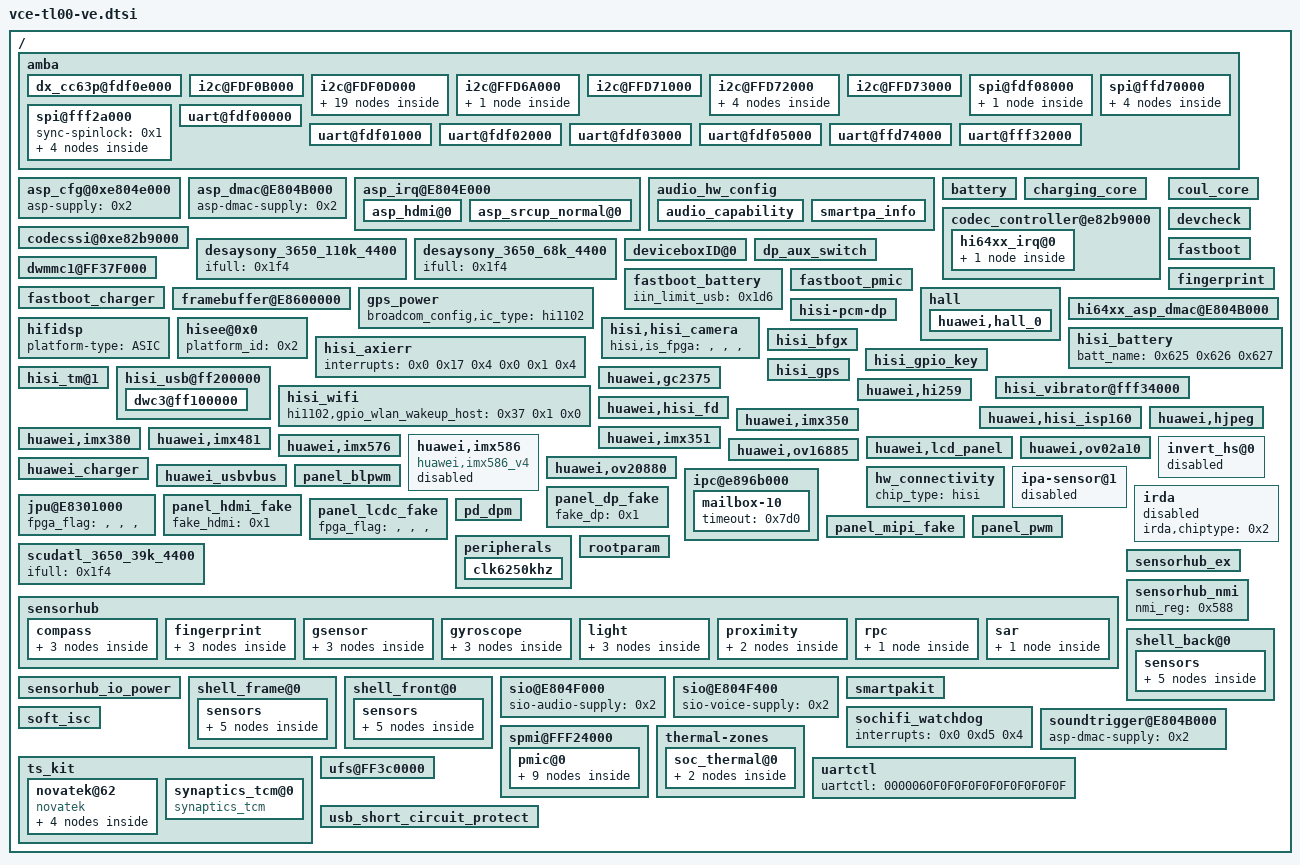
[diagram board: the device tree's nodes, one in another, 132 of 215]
// SPDX-License-Identifier: GPL-2.0
// Editable settings imported from vce-tl00-ve.dtbo.
/ {
	__symbols__ {
		ldo22 = "/spmi@FFF24000/pmic@0/ldo22@28";
		lv52134a_phy = "/amba/i2c@FDF0D000/lv52134a@42";
		rt4801h_phy = "/amba/i2c@FDF0D000/rt4801h@73";
		tps65132_phy = "/amba/i2c@FDF0D000/tps65132@3e";
	};
	amba {
		dx_cc63p@fdf0e000 {
			interrupt-parent = <0x1>;
			interrupts = <0x0 0x87 0x4>;
		};
		i2c@FDF0B000 {
			clock-rate = <0x0 0x69db9c0>;
			cs-gpios = <0x231 0x6 0x0 0x231 0x7 0x0>;
			pinctrl-0 = <0x32b 0x32d 0x419 0x41b>;
			pinctrl-1 = <0x32c 0x32e 0x41a 0x41c>;
			pinctrl-names = "default", "idle";
		};
		i2c@FDF0D000 {
			lv52134a@42 {
				compatible = "huawei,hw_lv52134a";
				phandle = <0x6d6>;
				reg = <0x42>;
				status = "ok";
			};
			rt4801h@73 {
				compatible = "huawei,hw_rt4801h";
				phandle = <0x6d7>;
				reg = <0x73>;
				status = "ok";
			};
			smartpa@34 {
				chip_id = "", "", "", "";
				chip_model = "tfa9874";
				chip_vendor = <0x4>;
				compatible = "huawei,smartpakit_i2c";
				dump_regs = <0x0 0x100 0x0>;
				status = "ok";
				version_regs = <0x3 0x1 0x0>;
				hw_reset {
					ctl_sequence = <0x1 0x1 0x0 0x1>;
					gpio_reset = <0x86>;
				};
				irq_handler {
					gpio_irq = <0xc8>;
					irq_flags = <0x2>;
					need_reset;
					rw_sequence = <0x10 0x1 0x0 0x11 0x1 0x0 0x13 0x1 0x0 0x14 0x1 0x0 0x40 0x1 0x0 0x41 0x1 0x0 0x42 0x1 0x0>;
				};
				regmap_cfg {
					cache_type = "", "", "", "";
					max_register = <0xff>;
					reg_bits = <0x8>;
					reg_defaults = <0x0 0x1801 0x1 0x14>;
					val_bits = <0x10>;
				};
			};
			smartpa@4C {
				chip_id = "", "", "", "";
				chip_model = "tas2562";
				chip_vendor = <0x4>;
				compatible = "huawei,smartpakit_i2c";
				dump_regs = <0x0 0x0 0x1 0x0 0x80 0x0 0x0 0x32 0x1 0x0 0x80 0x0 0x0 0x33 0x1 0x0 0x80 0x0 0x0 0x34 0x1 0x0 0x80 0x0>;
				reset_debounce_wait_time = <0x64>;
				status = "ok";
				version_regs = <0x0 0x0 0x1 0x7d 0x1 0x0>;
				hw_reset {
					ctl_sequence = <0x0 0x3 0x1 0x2>;
					gpio_reset = <0x86>;
				};
				irq_handler {
					gpio_irq = <0xc8>;
					irq_flags = <0x2>;
					need_reset;
					rw_sequence = <0x0 0x14 0x2 0x0 0x0 0x1 0x1a 0x1 0x0 0x1b 0x1 0x0 0x1f 0x1 0x0 0x20 0x1 0x0 0x24 0x1 0x0 0x25 0x1 0x0 0x2 0x1 0x0 0x78 0x1 0x0>;
				};
				regmap_cfg {
					cache_type = "", "", "", "";
					max_register = <0x80>;
					reg_bits = <0x8>;
					val_bits = <0x8>;
				};
			};
			smartpa@50 {
				chip_id = "", "", "", "";
				chip_model = "cs35l36";
				chip_vendor = <0x4>;
				compatible = "huawei,smartpakit_i2c";
				dump_regs = <0x0 0x1 0x0 0x8 0x1 0x0 0x2014 0x21 0x0 0x2400 0x1 0x0 0x2c04 0xd 0x0 0x3800 0x31 0x0 0x4004 0x1 0x0 0x4220 0x1 0x0 0x4300 0x1 0x0 0x4800 0x3d 0x0 0x4c00 0x1 0x0 0x4c20 0x15 0x0 0x6000 0x1 0x0 0x6404 0x11 0x0 0x6450 0x1 0x0 0x6800 0x9 0x0 0x6c04 0x1 0x0 0xd00000 0x4d 0x0 0xe02800 0x1 0x0>;
				reg = <0x50>;
				status = "ok";
				version_regs = <0x0 0x1 0x0>;
				hw_reset {
					ctl_sequence = <0x1 0x1 0x0 0x1>;
					gpio_reset = <0x86>;
				};
				irq_handler {
					gpio_irq = <0xc8>;
					irq_flags = <0x2>;
					need_reset;
					rw_sequence = <0xd00020 0x1 0x0 0xd00024 0x1 0x0 0xd00028 0x1 0x0 0xd0002c 0x1 0x0 0xd00000 0xffffffff 0x1 0xd00004 0xffffffff 0x1 0xd00008 0xffffffff 0x1 0xd0000c 0xffffffff 0x1>;
				};
				regmap_cfg {
					cache_type = "", "", "", "";
					max_register = <0xe0ffff>;
					reg_bits = <0x20>;
					val_bits = <0x20>;
				};
			};
			tps65132@3e {
				compatible = "huawei,hw_tps65132";
				phandle = <0x6d5>;
				reg = <0x3e>;
				status = "ok";
			};
			typec@1E {
				ptn5150h_gpio_enb = <0x1>;
				ptn5150h_typec,gpio_enb = <0x4f 0x2 0x0>;
				ptn5150h_typec,gpio_intb = <0x232 0x5 0x0>;
				status = "disabled";
				typec_trigger_otg = <0x1>;
			};
			typec@1d {
				pericom30216_gpio_enb = <0x1>;
				pericom30216_mdelay = <0x32>;
				pericom30216_typec,gpio_enb = <0x4f 0x2 0x0>;
				pericom30216_typec,gpio_intb = <0x232 0x5 0x0>;
				status = "disabled";
				typec_trigger_otg = <0x1>;
			};
			typec@21 {
				fusb301_gpio_enb = <0x1>;
				fusb301_typec,gpio_enb = <0x4f 0x2 0x0>;
				fusb301_typec,gpio_intb = <0x232 0x5 0x0>;
				status = "disabled";
				typec_trigger_otg = <0x1>;
			};
			typec@47 {
				status = "disabled";
				tusb320_gpio_enb = <0x1>;
				tusb320_mdelay = <0x32>;
				tusb320_typec,gpio_enb = <0x4f 0x2 0x0>;
				tusb320_typec,gpio_intb = <0x232 0x5 0x0>;
				typec_trigger_otg = <0x1>;
			};
		};
		i2c@FFD6A000 {
			hi6523_charger_i2c6@6B {
				bat_comp = <0x1e>;
				fcp_support = <0x1>;
				gpio_int = <0x59 0x6 0x0>;
				ico_current_mode = "", "", "", "";
				scp_support = "", "", "", "";
				vclamp = <0x64>;
			};
		};
		i2c@FFD71000 {
			pinctrl-0;
			pinctrl-1;
			pinctrl-names = "default", "idle";
		};
		i2c@FFD72000 {
			clock-rate = <0x0 0x200b200>;
			cs-gpios = <0x231 0x4 0x0 0x231 0x5 0x0>;
			pinctrl-0 = <0x327 0x329 0x415 0x417>;
			pinctrl-1 = <0x328 0x32a 0x416 0x418>;
			pinctrl-names = "default", "idle";
			fusb30x_i2c1@22 {
				fairchild,int_n = <0x232 0x5 0x0>;
			};
			rt1711_i2c1@4e {
				rt1711,irq_pin = <0x232 0x5 0x0>;
			};
			rt9748@67 {
				loadswitch_en = <0x2a 0x2 0x0>;
				loadswitch_int = <0x232 0x3 0x0>;
			};
			tusb422_i2c1@20 {
				ti,alert-gpio = <0x232 0x5 0x0>;
			};
		};
		i2c@FFD73000 {
			clock-rate = <0x0 0x200b200>;
			cs-gpios = <0x231 0x6 0x0 0x231 0x7 0x0>;
			pinctrl-0 = <0x32b 0x32d 0x419 0x41b>;
			pinctrl-1 = <0x32c 0x32e 0x41a 0x41c>;
			pinctrl-names = "default", "idle";
		};
		spi@fdf08000 {
			clock-rate = <0x124f800>;
			pinctrl-0 = <0x285 0x287 0x289 0x370 0x372 0x374>;
			pinctrl-1 = <0x286 0x288 0x28a 0x371 0x373 0x375>;
			pinctrl-names = "default", "idle";
			spi_dev10@10 {
				pl022,com-mode = "", "", "", "";
				pl022,ctrl-len = <0x7>;
				pl022,duplex = "", "", "", "";
				pl022,interface = "", "", "", "";
				pl022,rx-level-trig = <0x3>;
				pl022,slave-tx-disable = "", "", "", "";
				pl022,tx-level-trig = <0x3>;
				pl022,wait-state = "", "", "", "";
				reg = "", "", "", "";
				spi-max-frequency = <0x186a0>;
			};
		};
		spi@ffd70000 {
			clock-rate = <0x0 0x802c800>;
			hardware-mutex = <0x1>;
			spi_dev0@0 {
				pl022,com-mode = "", "", "", "";
				pl022,ctrl-len = <0x7>;
				pl022,duplex = "", "", "", "";
				pl022,interface = "", "", "", "";
				pl022,rx-level-trig = <0x3>;
				pl022,slave-tx-disable = "", "", "", "";
				pl022,tx-level-trig = <0x3>;
				pl022,wait-state = "", "", "", "";
				spi-max-frequency = <0x186a0>;
			};
			spi_dev1@1 {
				pl022,com-mode = <0x1>;
				pl022,ctrl-len = <0x7>;
				pl022,duplex = "", "", "", "";
				pl022,interface = "", "", "", "";
				pl022,rx-level-trig = <0x3>;
				pl022,slave-tx-disable = "", "", "", "";
				pl022,tx-level-trig = <0x3>;
				pl022,wait-state = "", "", "", "";
				reg = <0x1>;
				spi-max-frequency = <0xc65d40>;
			};
			spi_dev2@2 {
				pl022,com-mode = <0x2>;
				pl022,ctrl-len = <0x7>;
				pl022,duplex = "", "", "", "";
				pl022,interface = "", "", "", "";
				pl022,rx-level-trig = <0x3>;
				pl022,slave-tx-disable = "", "", "", "";
				pl022,tx-level-trig = <0x3>;
				pl022,wait-state = "", "", "", "";
				reg = <0x2>;
				spi-max-frequency = <0xc65d40>;
			};
			spi_dev3@3 {
				pl022,com-mode = "", "", "", "";
				pl022,ctrl-len = <0x7>;
				pl022,duplex = "", "", "", "";
				pl022,interface = "", "", "", "";
				pl022,rx-level-trig = <0x3>;
				pl022,slave-tx-disable = "", "", "", "";
				pl022,tx-level-trig = <0x3>;
				pl022,wait-state = "", "", "", "";
				reg = <0x3>;
				spi-max-frequency = <0xc65d40>;
			};
		};
		spi@fff2a000 {
			sync-spinlock = <0x1>;
			spi_dev30@30 {
				pl022,com-mode = "", "", "", "";
				pl022,ctrl-len = <0x7>;
				pl022,duplex = "", "", "", "";
				pl022,interface = "", "", "", "";
				pl022,rx-level-trig = <0x3>;
				pl022,slave-tx-disable = "", "", "", "";
				pl022,tx-level-trig = <0x3>;
				pl022,wait-state = "", "", "", "";
				reg = "", "", "", "";
				spi-max-frequency = <0x186a0>;
			};
			spi_dev31@31 {
				pl022,com-mode = <0x1>;
				pl022,ctrl-len = <0x7>;
				pl022,duplex = "", "", "", "";
				pl022,interface = "", "", "", "";
				pl022,rx-level-trig = <0x3>;
				pl022,slave-tx-disable = "", "", "", "";
				pl022,tx-level-trig = <0x3>;
				pl022,wait-state = "", "", "", "";
				reg = <0x1>;
				spi-max-frequency = <0xc65d40>;
			};
			spi_dev32@32 {
				pl022,com-mode = <0x2>;
				pl022,ctrl-len = <0x7>;
				pl022,duplex = "", "", "", "";
				pl022,interface = "", "", "", "";
				pl022,rx-level-trig = <0x3>;
				pl022,slave-tx-disable = "", "", "", "";
				pl022,tx-level-trig = <0x3>;
				pl022,wait-state = "", "", "", "";
				reg = <0x2>;
				spi-max-frequency = <0xc65d40>;
			};
			spi_dev33@33 {
				pl022,com-mode = "", "", "", "";
				pl022,ctrl-len = <0x7>;
				pl022,duplex = "", "", "", "";
				pl022,interface = "", "", "", "";
				pl022,rx-level-trig = <0x3>;
				pl022,slave-tx-disable = "", "", "", "";
				pl022,tx-level-trig = <0x3>;
				pl022,wait-state = "", "", "", "";
				reg = <0x3>;
				spi-max-frequency = <0xc65d40>;
			};
		};
		uart@fdf00000 {
			clock-rate = <0x0 0x69db9c0>;
			pinctrl-0;
			pinctrl-1;
			pinctrl-names = "default", "idle";
			reset-enable-flag = <0x1>;
		};
		uart@fdf01000 {
			clock-rate = <0x0 0x69db9c0>;
			pinctrl-0 = <0x2bf 0x2c1 0x2c3 0x2c5 0x3a8 0x3aa 0x3ac 0x3ae>;
			pinctrl-1 = <0x2c0 0x2c2 0x2c4 0x2c6 0x3a9 0x3ab 0x3ad 0x3af>;
			pinctrl-names = "default", "idle";
			reset-enable-flag = <0x1>;
		};
		uart@fdf02000 {
			clock-rate = <0x0 0x124f800>;
			dma-names = "", "";
			dmas;
			pinctrl-0 = <0x2b1 0x2b3 0x39a 0x39c>;
			pinctrl-1 = <0x2b2 0x2b4 0x39b 0x39d>;
			pinctrl-names = "default", "idle";
		};
		uart@fdf03000 {
			clock-rate = <0x0 0x69db9c0>;
			pinctrl-0;
			pinctrl-1;
			pinctrl-names = "default", "idle";
			reset-enable-flag = <0x1>;
		};
		uart@fdf05000 {
			clock-rate = <0x0 0x69db9c0>;
			pinctrl-0 = <0x2b9 0x3b 0x2bb 0x2bd 0x3a2 0x3e 0x3a4 0x3a6>;
			pinctrl-1 = <0x2ba 0x40 0x2bc 0x2be 0x3a3 0x43 0x3a5 0x3a7>;
			pinctrl-names = "default", "idle";
			reset-enable-flag = <0x1>;
		};
		uart@ffd74000 {
			clock-rate = <0x0 0x5f5e100>;
			pinctrl-0;
			pinctrl-1;
			pinctrl-names = "default", "idle";
		};
		uart@fff32000 {
			clock-rate = <0x0 0x124f800>;
			console-fifo-cpuon = <0x3>;
			console-fifo-enable = <0x1>;
			console-fifo-size = <0x40000>;
			pinctrl-0 = <0x2b5 0x2b7 0x39e 0x3a0>;
			pinctrl-1 = <0x2b6 0x2b8 0x39f 0x3a1>;
			pinctrl-names = "default", "idle";
		};
	};
	asp_cfg@0xe804e000 {
		asp-supply = <0x2>;
	};
	asp_dmac@E804B000 {
		asp-dmac-supply = <0x2>;
	};
	asp_irq@E804E000 {
		asp_hdmi@0 {
			interrupt-names = "asp_irq_hdmi";
			interrupt-parent = <0x254>;
			interrupts = "", "", "", "", "", "", "", "";
		};
		asp_srcup_normal@0 {
			asp-srcup-normal-supply = <0x2>;
			interrupt-names = "asp_srcup_normal";
			interrupt-parent = <0x254>;
			interrupts = <0x1 0x0>;
		};
	};
	audio_hw_config {
		analog_earpiece_enable = "false";
		audio_sar_support = "true";
		codec_dsp_algo = "mad";
		codec_name = "DA_combine_v3";
		cust_name = "audio_custom";
		karaoke_mic_conf_support = "true";
		product_name = "VCE";
		spk_pa_name = "smartpakit";
		vqm_enable = "true";
		audio_capability {
			lvm_support = "false";
			playback_effect_used = "sws";
			usb_compatibility_report = "true";
			wakeup_internal_engine = "true";
		};
		smartpa_info {
			status = "ok";
		};
	};
	battery {
		battery_board_type = <0x2>;
		battery_design_fcc = <0xea6>;
	};
	charging_core {
		ichg_ac = <0x834>;
		ichg_fcp = <0xe10>;
		iin_fcp = <0x7d0>;
		iin_usb = <0x1d6>;
		inductance_para = "-32767", "15", "2000", "0", "15", "32767", "2000", "0";
		iterm = <0x96>;
	};
	codec_controller@e82b9000 {
		gpios = <0x59 0x4 0x0>;
		pm_runtime_support;
		hi64xx_irq@0 {
			hi6403_codec@0 {
				hisilicon,hs_4_pole_min_voltage = <0x384>;
				hisilicon,hs_extern_cable_max_voltage = <0xa8c>;
				hisilicon,hs_extern_cable_min_voltage = <0xa5b>;
				hisilicon,wakeup_audio_algo_support = <0x1>;
				hs_detect_extern_cable = <0x1>;
			};
		};
	};
	codecssi@0xe82b9000 {
		status = "ok";
	};
	coul_core {
		adc_batt_id = <0xb>;
		adc_batt_temp = <0xa>;
		current_full_enable = <0x1>;
		iscd_enable = <0x1>;
		last_soc_enable = <0x1>;
		normal_cutoff_vol_mv = <0xb54>;
		r_pcb = "", "", "", "";
		soc_at_term = <0x62>;
	};
	desaysony_3650_110k_4400 {
		ifull = <0x1f4>;
	};
	desaysony_3650_68k_4400 {
		ifull = <0x1f4>;
	};
	devcheck {
		charge = <0x3>;
		compass = <0x3>;
		g_sensor = <0x3>;
		gyroscope = <0x3>;
		l_sensor = <0x2>;
		touch_panel = <0x2>;
		tps = <0x3>;
	};
	deviceboxID@0 {
		box_num = <0x1>;
		check_mode = "gpio";
		deviceboxID_limit = <0x1f4>;
		enable_boxID = <0x1 0x0 0x0 0x0>;
		gpio_num = <0x1 0x0 0x0 0x0>;
		gpio_speakerID = <0x4c1 0x1 0x0>;
		pinctrl-0 = <0x45d 0x466>;
		pinctrl-1 = <0x45e 0x467>;
		pinctrl-names = "default", "idle";
		speaker_map = <0x1 0x1>;
		status = "ok";
	};
	dp_aux_switch {
		cs-gpios = <0x4f 0x1 0x0 0x4f 0x2 0x0>;
		pinctrl-0 = <0x287 0x289 0x372 0x374>;
		pinctrl-1 = <0x288 0x28a 0x373 0x375>;
		pinctrl-names = "default", "idle";
	};
	dwmmc1@FF37F000 {
		cd-gpio = <0x39 0x5 0x0>;
		cd-vol = <0x1>;
		cs_sd_timing_config;
		shared-irq = <0x1>;
		vmmc-supply = <0x5d3>;
		vqmmc-supply = <0xc8>;
	};
	fastboot {
		gpio-keydown = <0xe6>;
		gpio-keyup = <0xe7>;
		i2c-sel0-gpio = <0x2c>;
		i2c-sel0-val = "", "", "", "";
		i2c-sel1-gpio = <0x2d>;
		i2c-sel1-val = "", "", "", "";
		i2c-select = <0x1>;
		i2c3-pin = "", "", "", "";
		jtagtosd-board-type = <0x1>;
		lpm3-board-type = <0x2>;
		motor-vib_type = "", "", "", "";
		uart-board-type = <0x1>;
	};
	fastboot_battery {
		iin_limit_usb = <0x1d6>;
	};
	fastboot_charger {
		chip_i2c_num = <0x6>;
		hw_charger_type = <0x4>;
	};
	fastboot_pmic {
		hisilicon,init-reg-addrs = <0x243>;
		hisilicon,init-reg-num = <0x1>;
		hisilicon,init-reg-vals = <0x6>;
	};
	fingerprint {
		fingerprint,cs_gpio = <0xd8>;
		fingerprint,extern_ldo_name = "EXTERN_LDO";
		fingerprint,extern_ldo_num = <0x18>;
		fingerprint,extern_vol = <0x2b7cd0>;
		fingerprint,force_storage_type = <0x1>;
		fingerprint,fpc2050 = <0x1>;
		fingerprint,irq_gpio = <0xd2>;
		fingerprint,navigation_adjust1 = "", "", "", "";
		fingerprint,navigation_adjust2 = "", "", "", "";
		fingerprint,product = "venice";
		fingerprint,reset_gpio = <0xd3>;
		fingerprint,spi_num = <0x2>;
		fingreprint_ldo-supply = <0x5d7>;
		spi-max-frequency = <0x4c4b40>;
	};
	framebuffer@E8600000 {
		dss_version_tag = <0x40>;
		fpga_flag = "", "", "", "";
	};
	gps_power {
		broadcom_config,ic_type = "hi1102";
	};
	hall {
		huawei,hall_0 {
			huawei,default-state = "on";
			huawei,single-n-pole = <0x232 0x1 0x0>;
			huawei,type = <0x1>;
		};
	};
	hi64xx_asp_dmac@E804B000 {
		asp-dmac-supply = <0x2>;
		interrupt-names = "asp_dma_irq";
		interrupts = <0x0 0xd8 0x4>;
	};
	hifidsp {
		platform-type = "ASIC";
	};
	hisee@0x0 {
		platform_id = <0x2>;
	};
	hisi,hisi_camera {
		hisi,is_fpga = "", "", "", "";
	};
	hisi-pcm-dp {
		dp-pcm-supply = <0x2>;
		interrupt-names = "asp_hdmi_dma";
		interrupts = <0x0 0x96 0x4>;
	};
	hisi_axierr {
		interrupts = <0x0 0x17 0x4 0x0 0x1 0x4>;
	};
	hisi_battery {
		batt_name = <0x625 0x626 0x627>;
	};
	hisi_bfgx {
		have_ir;
		hi1102,irled_power_type = "", "", "", "";
	};
	hisi_gpio_key {
		gpio-keydown,gpio-irq = <0x5c 0x6 0x0>;
		gpio-keyup,gpio-irq = <0x5c 0x7 0x0>;
		pinctrl-0 = <0x455 0x451>;
		pinctrl-1 = <0x456 0x452>;
		pinctrl-names = "default", "idle";
	};
	hisi_gps {
		clock-names = "ref_clk", "mux_clk", "mdm_clk0", "mdm_clk1", "mdm_clk2";
		clocks = <0x563 0x160 0x161 0x162 0x163>;
		pinctrl-0 = <0x283 0x36e>;
		pinctrl-1 = <0x284 0x36f>;
		pinctrl-names = "default", "idle";
	};
	hisi_tm@1 {
		hisi,detect_flash_led_tm_chanel = <0x3>;
		hisi,detect_pa_1_tm_state = "disable";
		hisi,peripheral_sensors = <0x8>;
	};
	hisi_usb@ff200000 {
		eye_diagram_host_param = <0x2bde7e7>;
		eye_diagram_param = <0x33de7e7>;
		usb_aclk_freq = <0xe2f9780>;
		usb_support_check_voltage = "", "", "", "";
		usb_support_dp = <0x1>;
		dwc3@ff100000 {
			maximum-speed = "high-speed";
			quirk_dplus_gpio = "", "", "", "";
		};
	};
	hisi_vibrator@fff34000 {
		vibrator_vout_max_voltage = <0x2dc6c0>;
		vibrator_vout_min_voltage = <0x2dc6c0>;
	};
	hisi_wifi {
		hi1102,gpio_wlan_wakeup_host = <0x37 0x1 0x0>;
	};
	huawei,gc2375 {
		avdd-supply = <0x5da>;
		clock-names = "clk_isp_snclk0";
		clocks = <0x56e>;
		gpios = <0x4c1 0x0 0x0 0x5c 0x3 0x0 0x232 0x4 0x0>;
		huawei,csi_index = "", "", "", "";
		huawei,gpio-ctrl-types = "reset", "pwdn", "mipisw";
		huawei,i2c_index = "", "", "", "";
		huawei,is_fpga = "", "", "", "";
		huawei,ldo-names = "avdd", "iovdd", "vcm";
		huawei,mclk = <0x16e3600>;
		huawei,pd_valid = <0x1>;
		huawei,reset_valid = <0x1>;
		huawei,sensor_index = <0x4>;
		huawei,sensor_name = "GC2375VCE";
		huawei,vcmpd_valid = "", "", "", "";
		iovdd-supply = <0x5d6>;
		vcm-supply = <0x5d8>;
	};
	huawei,hi259 {
		avdd-supply = <0x5da>;
		clock-names = "clk_isp_snclk0";
		clocks = <0x56e>;
		gpios = <0x4c1 0x0 0x0 0x5c 0x3 0x0 0x232 0x4 0x0>;
		huawei,csi_index = "", "", "", "";
		huawei,gpio-ctrl-types = "reset", "pwdn", "mipisw";
		huawei,i2c_index = "", "", "", "";
		huawei,is_fpga = "", "", "", "";
		huawei,ldo-names = "avdd", "iovdd", "vcm";
		huawei,mclk = <0x16e3600>;
		huawei,pd_valid = <0x1>;
		huawei,reset_valid = <0x1>;
		huawei,sensor_index = <0x4>;
		huawei,sensor_name = "HI259VCE";
		huawei,vcmpd_valid = "", "", "", "";
		iovdd-supply = <0x5d6>;
		vcm-supply = <0x5d8>;
	};
	huawei,hisi_fd {
		clock-low-frequency = <0x1082af40>;
		clock-names = "clk_fd_func";
		clock-value = <0x11e1a300>;
		clocks = <0x5ba>;
		fd-pwr-seq = "fd_regulator", "fd_clk";
		fd_offset_list = <0x418 0x40c 0x410 0x414 0x464 0xfd 0x7a 0x9f 0x58 0x31c 0x470>;
		hisi-fd-supply = <0x1c4>;
		hisi-media-supply = <0x1cc>;
		huawei,smmu-flag = "", "", "", "";
		huawei,top-base = <0xe8304000 0x1000>;
		interrupts = <0x0 0x133 0x4>;
		mstr_offset_list = <0x28 0x34 0x100 0x260 0x3c0>;
		smmu_offset_list = <0x10 0x1c 0x20 0x204 0x20c 0x220 0x224>;
	};
	huawei,hisi_isp160 {
		hisi,is_fpga = "", "", "", "";
		pinctrl-0 = <0x295 0x297 0x299 0x29b 0x29d 0x29f 0x2a1 0x2a3 0x2a5 0x285 0x281 0x45b 0x28d 0x2ad 0x380 0x382 0x384 0x386 0x388 0x38a 0x38c 0x38e 0x390 0x370 0x36c 0x464 0x378 0x396>;
		pinctrl-1 = <0x296 0x298 0x29a 0x29c 0x29e 0x2a0 0x2a2 0x2a4 0x2a6 0x286 0x282 0x45c 0x28e 0x2ae 0x381 0x383 0x385 0x387 0x389 0x38b 0x38d 0x38f 0x391 0x371 0x36d 0x465 0x379 0x397>;
		pinctrl-names = "default", "idle";
	};
	huawei,hjpeg {
		clock-low-frequency = <0x1082af40>;
		clock-names = "clk_jpg_func";
		clock-value = <0x21055e80>;
		clocks = <0x237>;
		hjpeg-media-supply = <0x1cc>;
		hjpeg-srt-supply = <0x1c4>;
		huawei,chip_type = <0x1>;
		huawei,cvdr = "", "", "", "", "", "", "", "", "", "", "", "";
		huawei,cvdr-base = <0xe8302000 0x1000>;
		huawei,hjpeg-base = <0xe8300000 0x1000>;
		huawei,power_control = "", "", "", "";
		huawei,smmu-base = <0xe8320000 0x20000>;
		huawei,smmu_type = <0x1>;
		huawei,stream_id = <0x0 0x4 0x5>;
		huawei,subctrl-base = <0xe8304000 0x4>;
		interrupts = <0x0 0x12b 0x4>;
		power-off-frequency = <0xe2f9780>;
		reg = <0x0 0xe8300000 0x0 0x1000>;
	};
	huawei,imx350 {
		avdd-supply = <0x5db>;
		clock-names = "clk_isp_snclk1";
		clocks = <0x56f>;
		dvdd-supply = <0x5d5>;
		gpios = <0x4f 0x5 0x0>;
		huawei,csi_index = <0x1>;
		huawei,gpio-ctrl-types = "reset";
		huawei,i2c_index = <0x1>;
		huawei,is_fpga = "", "", "", "";
		huawei,ldo-names = "avdd", "vcm", "dvdd", "iovdd";
		huawei,mclk = <0x16e3600>;
		huawei,pd_valid = <0x1>;
		huawei,reset_valid = <0x1>;
		huawei,sensor_index = "", "", "", "";
		huawei,sensor_name = "IMX350VCE";
		huawei,vcmpd_valid = "", "", "", "";
		iovdd-supply = <0x5d6>;
		vcm-supply = <0x5d8>;
	};
	huawei,imx351 {
		avdd-supply = <0x5da>;
		clock-names = "clk_isp_snclk2";
		clocks = <0x570>;
		dvdd-supply = <0x5d4>;
		gpios = <0x4f 0x6 0x0>;
		huawei,csi_index = <0x2>;
		huawei,gpio-ctrl-types = "reset";
		huawei,i2c_index = <0x2>;
		huawei,is_fpga = "", "", "", "";
		huawei,ldo-names = "avdd", "dvdd", "iovdd";
		huawei,mclk = <0x16e3600>;
		huawei,pd_valid = <0x1>;
		huawei,reset_valid = <0x1>;
		huawei,sensor_index = <0x5>;
		huawei,sensor_name = "IMX351";
		huawei,vcmpd_valid = "", "", "", "";
		iovdd-supply = <0x5d6>;
	};
	huawei,imx380 {
		avdd-supply = <0x5d2>;
		clock-names = "clk_isp_snclk1";
		clocks = <0x56f>;
		dvdd-supply = <0x5d5>;
		gpios = <0x4f 0x5 0x0>;
		huawei,csi_index = <0x1>;
		huawei,gpio-ctrl-types = "reset";
		huawei,i2c_index = <0x1>;
		huawei,is_fpga = "", "", "", "";
		huawei,ldo-names = "avdd", "vcm", "dvdd", "iovdd";
		huawei,mclk = <0x16e3600>;
		huawei,pd_valid = <0x1>;
		huawei,reset_valid = <0x1>;
		huawei,sensor_index = "", "", "", "";
		huawei,sensor_name = "IMX380";
		huawei,vcmpd_valid = "", "", "", "";
		iovdd-supply = <0x5d6>;
		vcm-supply = <0x5d8>;
	};
	huawei,imx481 {
		avdd-supply = <0x5da>;
		clock-names = "clk_isp_snclk2";
		clocks = <0x570>;
		dvdd-supply = <0x5d4>;
		gpios = <0x4f 0x6 0x0>;
		huawei,csi_index = <0x2>;
		huawei,gpio-ctrl-types = "reset";
		huawei,i2c_index = <0x2>;
		huawei,is_fpga = "", "", "", "";
		huawei,ldo-names = "avdd", "dvdd", "iovdd";
		huawei,mclk = <0x16e3600>;
		huawei,pd_valid = <0x1>;
		huawei,reset_valid = <0x1>;
		huawei,sensor_index = <0x5>;
		huawei,sensor_name = "IMX481";
		huawei,vcmpd_valid = "", "", "", "";
		iovdd-supply = <0x5d6>;
	};
	huawei,imx576 {
		avdd-supply = <0x5d2>;
		avdd0-supply = <0x5d8>;
		clock-names = "clk_isp_snclk0";
		clocks = <0x56e>;
		dvdd-supply = <0x5d9>;
		gpios = <0x1d6 0x0 0x0 0x232 0x4 0x0>;
		huawei,csi_index = "", "", "", "";
		huawei,gpio-ctrl-types = "reset", "mipisw";
		huawei,i2c_index = "", "", "", "";
		huawei,is_fpga = "", "", "", "";
		huawei,ldo-names = "avdd", "dvdd", "iovdd", "avdd0";
		huawei,mclk = <0x16e3600>;
		huawei,pd_valid = <0x1>;
		huawei,reset_valid = <0x1>;
		huawei,sensor_index = <0x1>;
		huawei,sensor_name = "IMX576VCE";
		huawei,vcmpd_valid = "", "", "", "";
		iovdd-supply = <0x5d6>;
	};
	huawei,imx586 {
		avdd-supply = <0x5db>;
		avdd2-supply = <0x5d3>;
		clock-names = "clk_isp_snclk1";
		clocks = <0x56f>;
		compatible = "huawei,imx586_v4";
		dvdd-supply = <0x5d5>;
		dvdd2-supply = <0x6d3>;
		gpios = <0x4f 0x5 0x0 0x4c0 0x7 0x0>;
		huawei,csi_index = <0x1>;
		huawei,gpio-ctrl-types = "reset", "dvdd0-en";
		huawei,i2c_index = <0x1>;
		huawei,is_fpga = "", "", "", "";
		huawei,ldo-names = "avdd", "avdd2", "vcm", "dvdd", "dvdd2", "iovdd";
		huawei,mclk = <0x16e3600>;
		huawei,pd_valid = <0x1>;
		huawei,reset_valid = <0x1>;
		huawei,sensor_index = "", "", "", "";
		huawei,sensor_name = "IMX586";
		huawei,vcmpd_valid = "", "", "", "";
		iovdd-supply = <0x5d6>;
		status = "disable";
		vcm-supply = <0x5d8>;
	};
	huawei,lcd_panel {
		lcd_ldo_channel = <0x2>;
		lcd_ldo_name = "LDO4";
		lcd_ldo_threshold = <0xc8>;
	};
	huawei,ov02a10 {
		avdd-supply = <0x5da>;
		clock-names = "clk_isp_snclk0";
		clocks = <0x56e>;
		gpios = <0x4c1 0x0 0x0 0x5c 0x3 0x0 0x232 0x4 0x0>;
		huawei,csi_index = "", "", "", "";
		huawei,gpio-ctrl-types = "reset", "pwdn", "mipisw";
		huawei,i2c_index = "", "", "", "";
		huawei,is_fpga = "", "", "", "";
		huawei,ldo-names = "avdd", "iovdd", "vcm";
		huawei,mclk = <0x16e3600>;
		huawei,pd_valid = <0x1>;
		huawei,reset_valid = <0x1>;
		huawei,sensor_index = <0x4>;
		huawei,sensor_name = "OV02A10VCE";
		huawei,vcmpd_valid = "", "", "", "";
		iovdd-supply = <0x5d6>;
		vcm-supply = <0x5d8>;
	};
	huawei,ov16885 {
		avdd-supply = <0x5da>;
		clock-names = "clk_isp_snclk2";
		clocks = <0x570>;
		dvdd-supply = <0x5d4>;
		gpios = <0x4f 0x6 0x0>;
		huawei,csi_index = <0x2>;
		huawei,gpio-ctrl-types = "reset";
		huawei,i2c_index = <0x2>;
		huawei,is_fpga = "", "", "", "";
		huawei,ldo-names = "avdd", "dvdd", "iovdd";
		huawei,mclk = <0x16e3600>;
		huawei,pd_valid = <0x1>;
		huawei,reset_valid = <0x1>;
		huawei,sensor_index = <0x5>;
		huawei,sensor_name = "OV16885VCE";
		huawei,vcmpd_valid = "", "", "", "";
		iovdd-supply = <0x5d6>;
	};
	huawei,ov20880 {
		avdd-supply = <0x5db>;
		clock-names = "clk_isp_snclk1";
		clocks = <0x56f>;
		dvdd-supply = <0x5d5>;
		gpios = <0x4f 0x5 0x0>;
		huawei,csi_index = <0x1>;
		huawei,gpio-ctrl-types = "reset";
		huawei,i2c_index = <0x1>;
		huawei,is_fpga = "", "", "", "";
		huawei,ldo-names = "avdd", "vcm", "dvdd", "iovdd";
		huawei,mclk = <0x16e3600>;
		huawei,pd_valid = <0x1>;
		huawei,reset_valid = <0x1>;
		huawei,sensor_index = "", "", "", "";
		huawei,sensor_name = "OV20880VCE";
		huawei,vcmpd_valid = "", "", "", "";
		iovdd-supply = <0x5d6>;
		vcm-supply = <0x5d8>;
	};
	huawei_charger {
		fcp_vindpm = <0x1fa4>;
		pd_support = <0x1>;
		support_usb_nonstandard_ico = <0x1>;
	};
	huawei_usbvbus {
		enable_wired_channel = <0x1>;
		pmic_vbus_attach_enable = "", "", "", "";
		pmic_vbus_enable = <0x1>;
		support_pd = <0x1>;
	};
	hw_connectivity {
		chip_type = "hisi";
	};
	invert_hs@0 {
		gpio_type = "", "", "", "";
		gpios = "", "", "", "+", "", "", "", "", "", "", "";
		pinctrl-0 = <0x341 0x42f>;
		pinctrl-1 = <0x342 0x430>;
		pinctrl-names = "default", "idle";
		status = "disabled";
	};
	ipa-sensor@1 {
		status = "disabled";
	};
	ipc@e896b000 {
		mailbox-10 {
			timeout = <0x7d0>;
		};
	};
	irda {
		irda,chiptype = <0x2>;
		status = "disabled";
	};
	jpu@E8301000 {
		fpga_flag = "", "", "", "";
	};
	panel_blpwm {
		#address-cells = <0x2>;
		#size-cells = <0x2>;
		clock-names = "clk_blpwm";
		clocks = <0x5aa>;
		fpga_flag = "", "", "", "";
		pinctrl-0 = <0x31f 0x321 0x40d 0x40f>;
		pinctrl-1 = <0x320 0x322 0x40e 0x410>;
		pinctrl-names = "default", "idle";
	};
	panel_dp_fake {
		fake_dp = <0x1>;
	};
	panel_hdmi_fake {
		fake_hdmi = <0x1>;
	};
	panel_lcdc_fake {
		#address-cells = <0x2>;
		#size-cells = <0x2>;
		fpga_flag = "", "", "", "";
	};
	panel_mipi_fake {
		#address-cells = <0x2>;
		#size-cells = <0x2>;
		bl_enable_flag = "", "", "", "";
		fpga_flag = "", "", "", "";
		gpio_nums = <0x22 0x33 0xc>;
		gpios = <0x1d6 0x2 0x0 0x5a 0x3 0x0 0x4f 0x4 0x0>;
		lcd-bl-ic-name = "LM36923YFFR";
	};
	panel_pwm {
		#address-cells = <0x2>;
		#size-cells = <0x2>;
		clock-names = "clk_pwm";
		clocks = <0x562>;
		fpga_flag = "", "", "", "";
	};
	pd_dpm {
		support_analog_audio = "", "", "", "";
		switch_manual_enable = "", "", "", "";
	};
	peripherals {
		clk6250khz {
			#clock-cells = "", "", "", "";
			clock-frequency = <0x601800>;
			clock-output-names = "clk6250khz";
		};
	};
	rootparam {
		hisi,boardid = <0x6 0x9 0x8 0x2>;
		hisi,boardname = "VCE_TL00_VE";
		hisi,dtbo_idx = <0x93>;
	};
	scudatl_3650_39k_4400 {
		ifull = <0x1f4>;
	};
	sensorhub {
		compass {
			mag1 {
				file_id = <0x25>;
				sensorlist_name = "mag-akm09911";
				softfilter = <0x2>;
				softiron_parameter = <0x10 0x27 0x0 0x0 0x0 0x0 0x0 0x0 0x10 0x27 0x0 0x0 0x0 0x0 0x0 0x0 0x10 0x27 0x0 0x0 0x0 0x0 0x0 0x0 0x0 0x0 0x0>;
				threshold_for_als_calibrate = <0xdac>;
				vendor = "akm";
			};
			mag2 {
				axis_map_x = <0x1>;
				axis_map_y = "", "", "", "";
				axis_map_z = <0x2>;
				bus_number = "", "", "", "";
				calibrate_method = <0x2>;
				chip_id_register = <0x80>;
				chip_id_value = <0x7>;
				file_id = <0x42>;
				negate_x = "", "", "", "";
				negate_y = "", "", "", "";
				negate_z = <0x1>;
				outbit = "", "", "", "";
				poll_interval = <0xa>;
				reg = <0x2e>;
				sensor_list_info_id = <0x1>;
				sensor_type = "mag";
				sensorlist_name = "mag-yas537";
				softfilter = <0x2>;
				softiron_parameter = <0x10 0x27 0x0 0x0 0x0 0x0 0x0 0x0 0x10 0x27 0x0 0x0 0x0 0x0 0x0 0x0 0x10 0x27 0x0 0x0 0x0 0x0 0x0 0x0 0x0 0x0 0x0>;
				threshold_for_als_calibrate = <0x7d0>;
				vendor = "yamaha";
			};
			mag3 {
				axis_map_x = <0x1>;
				axis_map_y = "", "", "", "";
				axis_map_z = <0x2>;
				bus_number = "", "", "", "";
				calibrate_method = <0x2>;
				chip_id_register = "", "", "", "";
				chip_id_value = <0x48>;
				file_id = <0x43>;
				gpio_int1 = "", "", "", "6", "", "", "", "", "", "", "";
				gpio_reset = "", "", "", "6", "", "", "", "", "", "", "";
				negate_x = "", "", "", "";
				negate_y = "", "", "", "";
				negate_z = <0x1>;
				outbit = "", "", "", "";
				poll_interval = <0xa>;
				reg = <0xc>;
				sensor_list_info_id = <0x1>;
				sensor_type = "mag";
				sensorlist_name = "akm-akm09918";
				softiron_parameter = <0x10 0x27 0x0 0x0 0x0 0x0 0x0 0x0 0x10 0x27 0x0 0x0 0x0 0x0 0x0 0x0 0x10 0x27 0x0 0x0 0x0 0x0 0x0 0x0 0x0 0x0 0x0>;
				threshold_for_als_calibrate = <0xdac>;
				vendor = "akm";
			};
		};
		fingerprint {
			finger1 {
				bus_number = <0x2>;
				bus_type = <0x1>;
				chip_id_register = <0xfc>;
				chip_id_value = <0x1023>;
				combo_bus_num = <0x2>;
				combo_bus_type = "spi";
				combo_data = <0xd8>;
				combo_rx_exp = [06 12 06 11 06 21];
				combo_rx_mask = [ff ff];
				combo_tx = [fc];
				file_id = <0x5c>;
				gpio_cs = <0xd8>;
				gpio_irq = <0xd2>;
				gpio_irq_sh = <0x3f5>;
				gpio_reset = <0xd3>;
				poll_interval = <0x1f4>;
				product_id_value = <0x36>;
				reg = "", "", "", "";
				sensor_list_info_id = <0x12>;
				sensor_type = "fingerprint";
			};
			finger2 {
				bus_number = <0x2>;
				bus_type = <0x1>;
				chip_id_register = <0xfc>;
				chip_id_value = <0x3658>;
				combo_bus_num = <0x2>;
				combo_bus_type = "spi";
				combo_data = <0xd8>;
				combo_rx_exp = <0x4000025>;
				combo_rx_mask = <0xff00ffff>;
				combo_tx = [f1];
				file_id = <0x6a>;
				gpio_cs = <0xd8>;
				gpio_irq = <0xd2>;
				gpio_irq_sh = <0x3f5>;
				gpio_reset = <0xd3>;
				poll_interval = <0x1f4>;
				product_id_value = <0x36>;
				reg = "", "", "", "";
				sensor_list_info_id = <0x12>;
				sensor_type = "fingerprint";
			};
			finger3 {
				bus_number = <0x2>;
				bus_type = <0x1>;
				chip_id_register = <0xfc>;
				chip_id_value = <0x1511>;
				combo_bus_num = <0x2>;
				combo_bus_type = "spi";
				combo_data = <0xd8>;
				combo_rx_exp = <0x10111012 0x10131023>;
				combo_rx_mask = [ff ff];
				combo_tx = [fc];
				file_id = <0x6b>;
				gpio_cs = <0xd8>;
				gpio_irq = <0xd2>;
				gpio_irq_sh = <0x3f5>;
				gpio_reset = <0xd3>;
				poll_interval = <0x1f4>;
				product_id_value = <0x36>;
				reg = "", "", "", "";
				sensor_list_info_id = <0x12>;
				sensor_type = "fingerprint";
			};
		};
		gsensor {
			acc1 {
				calibrate_style = "", "", "", "";
				chip_id_register = "", "", "", "";
				chip_id_value = <0xd1>;
				compatible = "huawei,acc_bmi160";
				file_id = <0x21>;
				gpio_int2 = <0x39 0x7 0x0>;
				gpio_int2_sh = <0x3f2>;
				minDelay = <0xfa0>;
				negate_x = <0x1>;
				negate_z = <0x1>;
				reg = <0x68>;
				sensitivity_x = <0x1>;
				sensitivity_y = <0x1>;
				sensitivity_z = <0x1>;
				sensorlist_name = "accelerometer-bmi160";
				vendor = "bosch";
				x_calibrate_thredhold = <0xfa>;
				y_calibrate_thredhold = <0xfa>;
				z_calibrate_thredhold = <0x140>;
			};
			acc2 {
				axis_map_x = "", "", "", "";
				axis_map_y = <0x1>;
				axis_map_z = <0x2>;
				bus_number = "", "", "", "";
				calibrate_style = "", "", "", "";
				chip_id_register = <0xf>;
				chip_id_value = <0x69>;
				compatible = "huawei,acc_lsm6ds3";
				device_type = "", "", "", "";
				file_id = <0x22>;
				gpio_int1 = "", "", "", "+", "", "", "", "", "", "", "";
				gpio_int2 = <0x39 0x7 0x0>;
				gpio_int2_sh = <0x3f2>;
				minDelay = <0xfa0>;
				negate_x = "", "", "", "";
				negate_y = <0x1>;
				negate_z = <0x1>;
				offset_x = "", "", "", "";
				offset_y = "", "", "", "";
				offset_z = "", "", "", "";
				poll_interval = <0xa>;
				reg = <0x6a>;
				sensitivity_x = <0x1>;
				sensitivity_y = <0x1>;
				sensitivity_z = <0x1>;
				sensor_list_info_id = "", "", "", "";
				sensor_type = "acc";
				sensorlist_name = "accelerometer-lsm6ds3";
				vendor = "st";
				wakeup_duration = <0x20>;
				x_calibrate_thredhold = <0xfa>;
				y_calibrate_thredhold = <0xfa>;
				z_calibrate_thredhold = <0x140>;
			};
			acc3 {
				axis_map_x = "", "", "", "";
				axis_map_y = <0x1>;
				axis_map_z = <0x2>;
				bus_number = "", "", "", "";
				calibrate_style = "", "", "", "";
				chip_id_register = <0xf>;
				chip_id_value = <0x6a>;
				compatible = "huawei,acc_lsm6ds3-c";
				device_type = <0x1>;
				file_id = <0x22>;
				gpio_int1 = "", "", "", "+", "", "", "", "", "", "", "";
				gpio_int2 = <0x39 0x7 0x0>;
				gpio_int2_sh = <0x3f2>;
				minDelay = <0xfa0>;
				negate_x = "", "", "", "";
				negate_y = <0x1>;
				negate_z = <0x1>;
				offset_x = "", "", "", "";
				offset_y = "", "", "", "";
				offset_z = "", "", "", "";
				poll_interval = <0xa>;
				reg = <0x6a>;
				sensitivity_x = <0x1>;
				sensitivity_y = <0x1>;
				sensitivity_z = <0x1>;
				sensor_list_info_id = "", "", "", "";
				sensor_type = "acc";
				sensorlist_name = "accelerometer-lsm6ds3-c";
				vendor = "st";
				wakeup_duration = <0x20>;
				x_calibrate_thredhold = <0xfa>;
				y_calibrate_thredhold = <0xfa>;
				z_calibrate_thredhold = <0x140>;
			};
		};
		gyroscope {
			gyro1 {
				calibrate_thredhold = <0x116>;
				chip_id_register = "", "", "", "";
				chip_id_value = <0xd1>;
				file_id = <0x23>;
				gpio_int2 = <0x39 0x7 0x0>;
				gpio_int2_sh = <0x3f2>;
				minDelay = <0xfa0>;
				negate_x = <0x1>;
				negate_z = <0x1>;
				reg = <0x68>;
				sensorlist_name = "gyroscope-bmi160";
				vendor = "bosch";
			};
			gyro2 {
				axis_map_x = "", "", "", "";
				axis_map_y = <0x1>;
				axis_map_z = <0x2>;
				bus_number = "", "", "", "";
				calibrate_thredhold = <0x23c>;
				chip_id_register = <0xf>;
				chip_id_value = <0x69>;
				file_id = <0x24>;
				gpio_int1 = <0x2b 0x2 0x0>;
				gpio_int2 = <0x39 0x7 0x0>;
				gpio_int2_sh = <0x3f2>;
				minDelay = <0xfa0>;
				negate_x = "", "", "", "";
				negate_y = <0x1>;
				negate_z = <0x1>;
				poll_interval = <0xa>;
				reg = <0x6a>;
				sensor_list_info_id = <0x5>;
				sensor_type = "gyro";
				sensorlist_name = "gyroscope-lsm6ds3";
				still_calibrate_threshold = <0x14>;
				vendor = "st";
			};
			gyro3 {
				axis_map_x = "", "", "", "";
				axis_map_y = <0x1>;
				axis_map_z = <0x2>;
				bus_number = "", "", "", "";
				calibrate_thredhold = <0x23c>;
				chip_id_register = <0xf>;
				chip_id_value = <0x6a>;
				file_id = <0x24>;
				gpio_int1 = <0x2b 0x2 0x0>;
				gpio_int2 = <0x39 0x7 0x0>;
				gpio_int2_sh = <0x3f2>;
				minDelay = <0xfa0>;
				negate_x = "", "", "", "";
				negate_y = <0x1>;
				negate_z = <0x1>;
				poll_interval = <0xa>;
				reg = <0x6a>;
				sensor_list_info_id = <0x5>;
				sensor_type = "gyro";
				sensorlist_name = "gyroscope-lsm6ds3-c";
				still_calibrate_threshold = <0x14>;
				vendor = "st";
			};
		};
		light {
			als1 {
				als_phone_type = <0x2f>;
				chip_id_value = <0x72>;
				compatible = "huawei,B";
				file_id = <0x69>;
				gpio_int1 = <0x38 0x6 0x0>;
				is_cali_supported = <0x1>;
				reg = <0x29>;
				sensorlist_name = "als-b";
				vendor = "B";
			};
			als2 {
				GA1 = <0x1046>;
				GA2 = <0xf3c>;
				GA3 = <0x1194>;
				again = <0x1>;
				als_phone_type = <0x2f>;
				atime = <0xdb>;
				bus_number = "", "", "", "";
				chip_id_register = <0x91>;
				chip_id_value = <0x1 0x11 0x21 0x31>;
				compatible = "huawei,A";
				file_id = <0x68>;
				gpio_int1 = <0x38 0x6 0x0>;
				init_time = <0x96>;
				is_cali_supported = <0x1>;
				poll_interval = <0x15e>;
				reg = <0x39>;
				sensor_list_info_id = <0x3>;
				sensor_type = "als";
				sensorlist_name = "als-A";
				threshold_value = <0x1>;
				tp_color = "", "", "", "";
				vendor = "A";
			};
			als3 {
				GA1 = <0x1046>;
				GA2 = <0xf3c>;
				GA3 = <0x1194>;
				again = <0x1>;
				als_extend_data = "", "", "", "", "", "", "", "", "", "", "", "", "", "", "", "", "", "", "", "", "", "", "", "", "", "", "", "", "", "", "", "", "", "", "", "", "", "", "", "", "", "", "", "", "", "", "", "";
				als_phone_type = <0x2f>;
				als_phone_version = <0xa>;
				atime = <0xdb>;
				bus_number = "", "", "", "";
				chip_id_register = <0x92>;
				chip_id_value = <0x50>;
				compatible = "huawei,A";
				file_id = <0x68>;
				gpio_int1 = <0x38 0x6 0x0>;
				init_time = <0x96>;
				is_cali_supported = <0x1>;
				poll_interval = <0x15e>;
				reg = <0x29>;
				sensor_list_info_id = <0x3>;
				sensor_type = "als";
				sensorlist_name = "als-A";
				status = "ok";
				threshold_value = <0x1>;
				tp_color = "", "", "", "";
				vendor = "A";
			};
		};
		proximity {
			ps1 {
				chip_id_register = <0x7f>;
				chip_id_value = <0x11>;
				file_id = <0x6c>;
				gpio_int1 = <0x232 0x1 0x0>;
				max_near_pdata_loop = <0x4>;
				max_oily_add_pdata = <0x32>;
				min_proximity_value = <0xdc>;
				oily_count_size = <0xc>;
				oily_max_near_pdata = <0xe6>;
				poll_interval = <0x50>;
				ps_oily_threshold = <0x2>;
				pwave_value = <0xa>;
				pwindows_value = <0xa>;
				reg = <0x1e>;
				sensorlist_name = "proximity-pa224";
				threshold_value = <0x1f>;
				vendor = "txc";
			};
			ps2 {
				bus_number = "", "", "", "";
				chip_id_register = <0x6>;
				chip_id_value = <0xb1>;
				file_id = <0x31>;
				gpio_int1 = <0x232 0x1 0x0>;
				max_near_pdata_loop = <0x6>;
				max_oily_add_pdata = <0x6e>;
				min_proximity_value = <0xdc>;
				oily_count_size = <0x12>;
				oily_max_near_pdata = <0xfa>;
				poll_interval = <0x50>;
				ps_oily_threshold = <0x3>;
				pwave_value = <0xa>;
				pwindows_value = <0xa>;
				reg = <0x53>;
				sensor_list_info_id = <0x4>;
				sensor_type = "ps";
				sensorlist_name = "proximity-apds9110";
				threshold_value = <0x19>;
				vendor = "avago";
			};
		};
		rpc {
			rpc {
				compatible = "huawei,rpc";
				default_value = <0x1d>;
				file_id = <0x18>;
				mask = <0xffff 0x200 0x200 0xffff 0xffff 0xffff 0xffff 0xffff 0xffff 0xffff 0xffff 0xffff 0xffff 0xffff 0xffff 0xffff 0xffff 0xffff 0xffff 0xffff 0xffff 0xffff 0xffff 0xffff 0xffff 0xffff 0xffff 0xffff 0xffff 0xffff 0xffff 0xffff>;
				sensor_list_info_id = <0x18>;
				sensor_type = "rpc";
				sensorlist_name = "rpc";
				status = "ok";
				table = <0xffff 0x200 0x0 0xffff 0xffff 0xffff 0xffff 0xffff 0xffff 0xffff 0xffff 0xffff 0xffff 0xffff 0xffff 0xffff 0xffff 0xffff 0xffff 0xffff 0xffff 0xffff 0xffff 0xffff 0xffff 0xffff 0xffff 0xffff 0xffff 0xffff 0xffff 0xffff>;
			};
		};
		sar {
			sar1 {
				bus_number = "", "", "", "";
				calibrate_order = "0";
				calibrate_type = <0x5>;
				chip_id_register = "", "", "", "";
				chip_id_value = <0xa1 0x50>;
				chip_reg_bit16 = <0x1>;
				compatible = "huawei,adi-adux1050";
				file_id = <0x3a>;
				init_reg_val = <0x10206 0x20530 0x300cc 0x50f11 0x63964 0x70308 0x80200 0x90079 0xa0005 0x798000 0xb5846 0xc0308 0xd0200 0xe0042 0xf000c 0x7a8000>;
				poll_interval = <0x64>;
				reg = <0x2c>;
				sensor_list_info_id = <0x14>;
				sensor_type = "cap_prox";
				sensorlist_name = "cap_prox-adux1050";
				shared_flag = "", "", "", "";
				status = "disabled";
				to_ap_threshold = [00 c8 00 c9 00 00];
				to_modem_threshold = <0x7fbc05dc 0x3e80000 0x0 0x10 0x27100258 0x12c0000 0x0 0x0 0x0 0x0 0x0 0x0>;
				vendor = "ADI";
			};
		};
	};
	sensorhub_ex {
		adapt_file_id = <0x8 0x9 0xe 0xf>;
		adapt_sensor_list_id = <0x2 0x6 0x7 0x8 0xb 0xc 0xd 0xe 0xf 0x11 0x12 0x15 0x1d>;
		sensor_1v8_from_pmic = "no";
	};
	sensorhub_io_power {
		need-reset = <0x1>;
		sensor-io-supply = <0x5d7>;
		set-3v = <0x1>;
	};
	sensorhub_nmi {
		nmi_reg = <0x588>;
	};
	shell_back@0 {
		bias = <0x30d40>;
		count = <0x5>;
		tsensor_para = "10000", "100000", "0";
		sensors {
			sensor0 {
				coef = "45838", "12719", "3409", "-2588", "-18027";
				type = "usb_port";
			};
			sensor1 {
				coef = "15184", "333", "4625", "636", "-3387";
				type = "Battery";
			};
			sensor2 {
				coef = "7148", "1755", "1435", "3271", "-2206";
				type = "system_h";
			};
			sensor3 {
				coef = "36904", "13203", "7617", "7544", "-2120";
				type = "charger";
			};
			sensor4 {
				coef = "-3227", "-4973", "-3882", "-4425", "-19963";
				type = "pa_0";
			};
		};
	};
	shell_frame@0 {
		bias = <0x186a0>;
		count = <0x3>;
		tsensor_para = "10000", "100000", "0";
		sensors {
			sensor0 {
				coef = "30911", "9419", "10434";
				type = "usb_port";
			};
			sensor1 {
				coef = "10537", "-411", "7069";
				type = "Battery";
			};
			sensor2 {
				coef = "5914", "3267", "15419";
				type = "system_h";
			};
			sensor3 {
				coef = "13868", "5086", "5956";
				type = "charger";
			};
			sensor4 {
				coef = "-6756", "-6831", "-6191";
				type = "pa_0";
			};
		};
	};
	shell_front@0 {
		bias = <0x186a0>;
		count = <0x4>;
		tsensor_para = "10000", "100000", "0";
		sensors {
			sensor0 {
				coef = "25798", "7309", "6021", "16204";
				type = "usb_port";
			};
			sensor1 {
				coef = "6050", "2367", "2499", "6762";
				type = "Battery";
			};
			sensor2 {
				coef = "1079", "-1604", "-1452", "11492";
				type = "system_h";
			};
			sensor3 {
				coef = "8767", "1454", "1112", "14499";
				type = "charger";
			};
			sensor4 {
				coef = "-4027", "-5161", "-5344", "3115";
				type = "pa_0";
			};
		};
	};
	sio@E804F000 {
		sio-audio-supply = <0x2>;
	};
	sio@E804F400 {
		sio-voice-supply = <0x2>;
	};
	smartpakit {
		algo_in = "", "", "", "";
		dsp_img_name = "hifi_6403_imedia150_devkit.img";
		out_device = "", "", "", "";
		soc_platform = "", "", "", "";
		status = "ok";
	};
	sochifi_watchdog {
		interrupts = <0x0 0xd5 0x4>;
	};
	soft_isc {
		fatal_isc_trigger_condition = <0xc350 0x3 0x36d61a35 0x186a0 0x3 0x36d61a35>;
		fatal_isc_trigger_type = <0x1>;
		iscd_chrg_delay_cycles = <0xe>;
		iscd_delay_cycles_enable = <0x1>;
		iscd_file_magic_num = <0x115a3c77>;
	};
	soundtrigger@E804B000 {
		asp-dmac-supply = <0x2>;
	};
	spmi@FFF24000 {
		pmic@0 {
			gpios = "", "", "", "\\", "", "", "", "", "", "", "";
			hisilicon,pmic_fpga_flag = "", "", "", "";
			ldo22@28 {
				compatible = "hisilicon-hisi-ldo";
				hisilicon,hisi-ctrl = <0x28 0x1 0x0>;
				hisilicon,hisi-eco-microamp = <0x2710>;
				hisilicon,hisi-enable-time-us = <0x168>;
				hisilicon,hisi-n-voltages = <0x10>;
				hisilicon,hisi-off-on-delay-us = <0x4e20>;
				hisilicon,hisi-vset = <0x63 0xf>;
				hisilicon,hisi-vset-table = <0xe7ef0 0xf6950 0xf9060 0xfb770 0xfde80 0x100590 0x102ca0 0x1053b0 0x107ac0 0x10a1d0 0x10c8e0 0x10eff0 0x111700 0x113e10 0x116520 0x124f80>;
				hisilicon,valid-idle-mask = <0x9>;
				hisilicon,valid-modes-mask = <0x2>;
				phandle = <0x6d3>;
				regulator-max-microvolt = <0x124f80>;
				regulator-min-microvolt = <0xe7ef0>;
				regulator-name = "ldo22";
			};
			pmic_led@a0 {
				led@a0 {
					hisilicon,each_max_iset = <0x4>;
				};
				led@a1 {
					hisilicon,each_max_iset = "", "", "", "";
				};
				led@a2 {
					hisilicon,each_max_iset = <0x2>;
				};
			};
			pmic_mntn@a0 {
				OCP@218 {
					hisilicon,inacceptable-event = <0x27>;
				};
			};
			sim0 {
				allocate_gpio = <0x1>;
				card_tray_style = <0x1>;
				det_debounce_wait_time = <0x12c>;
				hpd_interrupt_to_close_ldo = <0xa>;
				pmu_ldo11_onoff_eco_address = <0x1d>;
				pmu_ldo11_onoff_value = <0x3>;
				pmu_ldo11_vset_address = <0x58>;
				pmu_ldo11_vset_value = <0x1>;
				pmu_ldo12_onoff_eco_address = <0x1e>;
				pmu_ldo12_onoff_value = <0x3>;
				pmu_ldo12_vset_address = <0x59>;
				pmu_ldo12_vset_value = <0x1>;
				pmu_sim_ctrl_address = <0x169>;
				pmu_sim_deb_ctrl_address = <0x16b>;
				pmu_status1_address = <0x7>;
				send_msg_to_cp = <0x1>;
				shared_det_irq = <0x1>;
			};
			sim1 {
				card_tray_style = <0x1>;
				det_debounce_wait_time = <0x12c>;
				hpd_interrupt_to_close_ldo = <0xa>;
				pmu_ldo11_onoff_eco_address = <0x1d>;
				pmu_ldo11_onoff_value = <0x3>;
				pmu_ldo11_vset_address = <0x58>;
				pmu_ldo11_vset_value = <0x1>;
				pmu_ldo12_onoff_eco_address = <0x1e>;
				pmu_ldo12_onoff_value = <0x3>;
				pmu_ldo12_vset_address = <0x59>;
				pmu_ldo12_vset_value = <0x1>;
				pmu_sim_ctrl_address = <0x169>;
				pmu_sim_deb_ctrl_address = <0x16b>;
				pmu_status1_address = <0x7>;
				send_msg_to_cp = <0x1>;
				shared_det_irq = <0x1>;
				status = "ok";
			};
		};
	};
	thermal-zones {
		soc_thermal@0 {
			trips {
				trip-point@1 {
					temperature = <0x124f8>;
				};
			};
		};
	};
	ts_kit {
		aft_enable = <0x1>;
		drv_stop_width = "", "", "", "";
		hide_plain_id = <0x1>;
		lcd_height = "", "", "", "";
		lcd_width = "", "", "", "";
		pl022,com-mode = <0x1>;
		product = "vce";
		novatek@62 {
			algo_id = <0x1>;
			charger_supported = <0x1>;
			compatible = "novatek";
			default_projectid = "VENC71140";
			glove_mode_supported = "", "", "", "";
			i2c_retry_time = <0x32>;
			ic_type = <0x2>;
			irq_config = <0x3>;
			noise_test_frame = <0x1e>;
			novatec-io-supply;
			novatek-vdd-supply;
			nvttddi_channel_flag = <0x1>;
			open_test_by_fw = <0x1>;
			pinctrl-0 = <0x347 0x435>;
			pinctrl-1 = <0x348 0x436>;
			pinctrl-names = "default", "idle";
			power_sleep_mode = <0x1>;
			rawdate_pointer_to_pointer = <0x1>;
			report_priority = <0x0 0x3 0x8 0x7 0xc 0xff 0xff 0xff 0xff 0xff 0xff 0xff 0xff 0xff 0xff 0xff>;
			report_priority_limite = <0x32 0x14 0x14 0x32 0x32 0x32 0x32 0x32 0x32 0x32 0x32 0x32 0x32 0x32 0x32 0x32>;
			roi_supported = <0x1>;
			slave_address = <0x62>;
			support_aft = <0x1>;
			tp_status_report_support = <0x1>;
			tp_test_type = "Normalize_type:judge_last_result";
			use_dma_download_firmware = <0x1>;
			use_pinctrl = <0x1>;
			vci_gpio_type = "", "", "", "";
			vci_regulator_type = "", "", "", "";
			vddio_gpio_type = "", "", "", "";
			vddio_regulator_type = "", "", "", "";
			wx_support = <0x1>;
			x_max = <0x438>;
			x_max_mt = <0x438>;
			y_max = <0x906>;
			y_max_mt = <0x906>;
			VENC71110 {
				IC_X_CFG_SIZE = <0x12>;
				IC_Y_CFG_SIZE = <0x24>;
				NVT_TDDI_AIN_X = <0x0 0x1 0x2 0x3 0x4 0x5 0x6 0x7 0x8 0x9 0xa 0xb 0xc 0xd 0xe 0xf 0x10 0x11>;
				NVT_TDDI_AIN_Y = <0x0 0x1 0x2 0x3 0x4 0x5 0x6 0x7 0x8 0x9 0xa 0xb 0xc 0xd 0xe 0xf 0x10 0x11 0x12 0x13 0x14 0x15 0x16 0x17 0x18 0x19 0x1a 0x1b 0x1c 0x1d 0x1e 0x1f 0x20 0x21 0x22 0x23>;
				NvtTddi_X_Channel = <0x12>;
				NvtTddi_Y_Channel = <0x24>;
				compatible = "VENC71110";
				criteria_threshold_flag = <0x1>;
				glove_mode_supported = "", "", "", "";
				huawei,csvfile_use_system = <0x2>;
				huawei,test_capacitance_via_csvfile = <0x1>;
				mADCOper_Cnt = <0x2>;
				nvttddi_channel_flag = <0x1>;
				producer = "110";
				roi_supported = <0x1>;
				touch_switch_flag = <0x4>;
			};
			VENC71130 {
				IC_X_CFG_SIZE = <0x12>;
				IC_Y_CFG_SIZE = <0x24>;
				NVT_TDDI_AIN_X = <0x0 0x1 0x2 0x3 0x4 0x5 0x6 0x7 0x8 0x9 0xa 0xb 0xc 0xd 0xe 0xf 0x10 0x11>;
				NVT_TDDI_AIN_Y = <0x0 0x1 0x2 0x3 0x4 0x5 0x6 0x7 0x8 0x9 0xa 0xb 0xc 0xd 0xe 0xf 0x10 0x11 0x12 0x13 0x14 0x15 0x16 0x17 0x18 0x19 0x1a 0x1b 0x1c 0x1d 0x1e 0x1f 0x20 0x21 0x22 0x23>;
				NvtTddi_X_Channel = <0x12>;
				NvtTddi_Y_Channel = <0x24>;
				compatible = "VENC71130";
				criteria_threshold_flag = <0x1>;
				glove_mode_supported = "", "", "", "";
				huawei,csvfile_use_system = <0x2>;
				huawei,test_capacitance_via_csvfile = <0x1>;
				mADCOper_Cnt = <0x2>;
				nvttddi_channel_flag = <0x1>;
				producer = "130";
				roi_supported = <0x1>;
				touch_switch_flag = <0x4>;
			};
			VENC71140 {
				IC_X_CFG_SIZE = <0x12>;
				IC_Y_CFG_SIZE = <0x24>;
				NVT_TDDI_AIN_X = <0x0 0x1 0x2 0x3 0x4 0x5 0x6 0x7 0x8 0x9 0xa 0xb 0xc 0xd 0xe 0xf 0x10 0x11>;
				NVT_TDDI_AIN_Y = <0x0 0x1 0x2 0x3 0x4 0x5 0x6 0x7 0x8 0x9 0xa 0xb 0xc 0xd 0xe 0xf 0x10 0x11 0x12 0x13 0x14 0x15 0x16 0x17 0x18 0x19 0x1a 0x1b 0x1c 0x1d 0x1e 0x1f 0x20 0x21 0x22 0x23>;
				NvtTddi_X_Channel = <0x12>;
				NvtTddi_Y_Channel = <0x24>;
				compatible = "VENC71140";
				criteria_threshold_flag = <0x1>;
				glove_mode_supported = "", "", "", "";
				huawei,csvfile_use_system = <0x2>;
				huawei,test_capacitance_via_csvfile = <0x1>;
				mADCOper_Cnt = <0x2>;
				nvttddi_channel_flag = <0x1>;
				producer = "140";
				roi_supported = <0x1>;
				touch_switch_flag = <0x4>;
			};
			VENC71170 {
				IC_X_CFG_SIZE = <0x12>;
				IC_Y_CFG_SIZE = <0x24>;
				NVT_TDDI_AIN_X = <0x0 0x1 0x2 0x3 0x4 0x5 0x6 0x7 0x8 0x9 0xa 0xb 0xc 0xd 0xe 0xf 0x10 0x11>;
				NVT_TDDI_AIN_Y = <0x0 0x1 0x2 0x3 0x4 0x5 0x6 0x7 0x8 0x9 0xa 0xb 0xc 0xd 0xe 0xf 0x10 0x11 0x12 0x13 0x14 0x15 0x16 0x17 0x18 0x19 0x1a 0x1b 0x1c 0x1d 0x1e 0x1f 0x20 0x21 0x22 0x23>;
				NvtTddi_X_Channel = <0x12>;
				NvtTddi_Y_Channel = <0x24>;
				compatible = "VENC71170";
				criteria_threshold_flag = <0x1>;
				glove_mode_supported = "", "", "", "";
				huawei,csvfile_use_system = <0x2>;
				huawei,test_capacitance_via_csvfile = <0x1>;
				mADCOper_Cnt = <0x2>;
				nvttddi_channel_flag = <0x1>;
				producer = "170";
				roi_supported = <0x1>;
				touch_switch_flag = <0x4>;
			};
		};
		synaptics_tcm@0 {
			aft_wxy_enable = <0x1>;
			charger_supported = <0x1>;
			compatible = "synaptics_tcm";
			default_project_id = "VENC69170";
			downmload_firmware_frequency = <0x7a1200>;
			glove_supported = "", "", "", "";
			ic_type = <0x6>;
			irq_config = "", "", "", "";
			max_finger_objects = <0xa>;
			pinctrl-0 = <0x347 0x435>;
			pinctrl-1 = <0x348 0x436>;
			pinctrl-names = "default", "idle";
			rawdata_newformatflag = <0x1>;
			reg = "", "", "", "";
			report_priority = <0x0 0x3 0x8 0x7 0xc 0xff 0xff 0xff 0xff 0xff 0xff 0xff 0xff 0xff 0xff 0xff>;
			report_priority_limite = <0x32 0x14 0x14 0x32 0x32 0x32 0x32 0x32 0x32 0x32 0x32 0x32 0x32 0x32 0x32 0x32>;
			roi_supported = <0x1>;
			spi-max-frequency = <0x989680>;
			synaptics,block-delay-us = "", "", "", "";
			synaptics,byte-delay-us = "", "", "", "";
			synaptics,irq-on-state = "", "", "", "";
			synaptics,power-delay-ms = <0xc8>;
			synaptics,reset-active-ms = <0x14>;
			synaptics,reset-delay-ms = <0xc8>;
			synaptics,reset-on-state = "", "", "", "";
			synaptics,spi-mode = <0x3>;
			synaptics,ubl-byte-delay-us = "", "", "", "";
			synaptics,ubl-max-freq = <0x4c4b40>;
			touch_switch_flag = <0x4>;
			tp_status_report_support = <0x1>;
			use_dma_download_firmware = <0x1>;
			use_esd_report = <0x1>;
			use_pinctrl = <0x1>;
			vci_gpio_type = "", "", "", "";
			vci_regulator_type = "", "", "", "";
			vddio_gpio_type = "", "", "", "";
			vddio_regulator_type = "", "", "", "";
			x_max = <0x438>;
			x_max_mt = <0x438>;
			y_max = <0x906>;
			y_max_mt = <0x906>;
		};
	};
	uartctl {
		uartctl = "0000060F0F0F0F0F0F0F0F0F0F";
	};
	ufs@FF3c0000 {
		ufs-kirin-broken-clk-gate-bypass;
		ufs-kirin-broken-fastauto;
		ufs-kirin-unipro-termination;
		ufs-kirin-use-HS-GEAR3;
		ufs-kirin-use-rate-B;
	};
	usb_short_circuit_protect {
		close_mosfet_temp = <0xa>;
		interval_switch_temp = <0xf>;
		open_mosfet_temp = <0x14>;
	};
};
